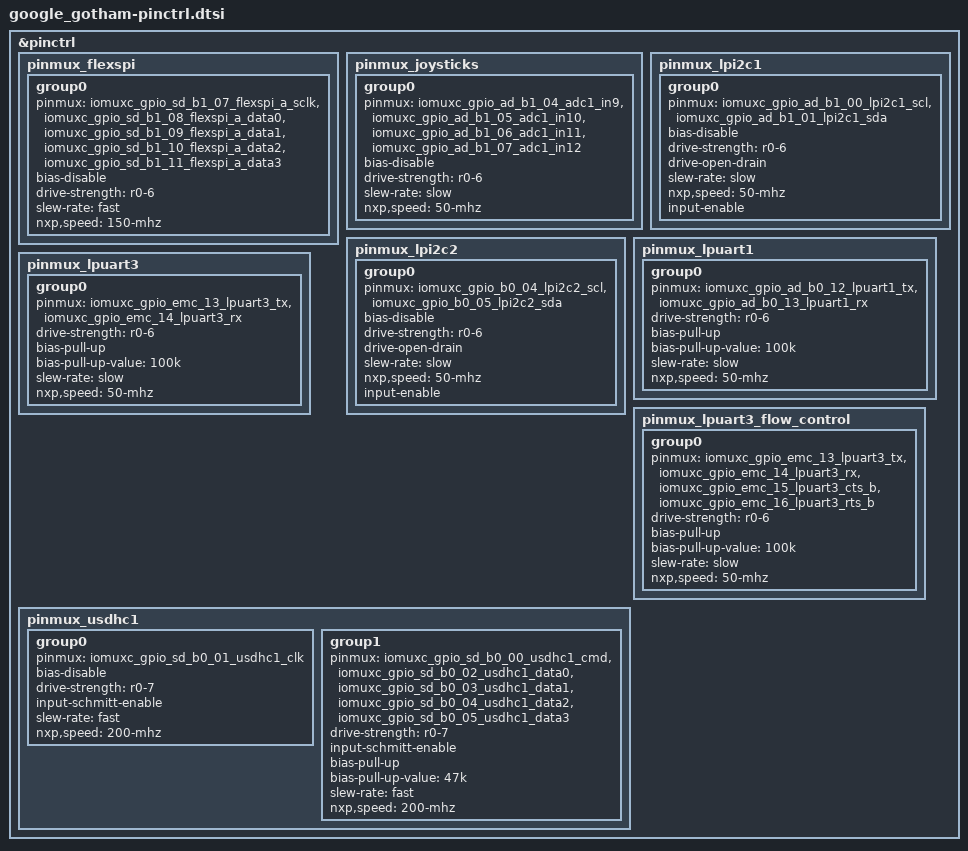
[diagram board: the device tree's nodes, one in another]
/*
 * Copyright 2025 NXP
 * All rights reserved.
 *
 * SPDX-License-Identifier: BSD-3-Clause
 */

/***********************************************************************************************************************
 * This file was generated by the MCUXpresso Config Tools. Any manual edits made to this file
 * will be overwritten if the respective MCUXpresso Config Tools is used to update this file.
 **********************************************************************************************************************/

#include <nxp/nxp_imx/rt/mimxrt1062dvl6a-pinctrl.dtsi>

&pinctrl {

	/* Configures pin routing and optionally pin electrical features. */
	pinmux_flexspi: pinmux_flexspi {
		group0 {
			pinmux = <&iomuxc_gpio_sd_b1_07_flexspi_a_sclk>,
				<&iomuxc_gpio_sd_b1_08_flexspi_a_data0>,
				<&iomuxc_gpio_sd_b1_09_flexspi_a_data1>,
				<&iomuxc_gpio_sd_b1_10_flexspi_a_data2>,
				<&iomuxc_gpio_sd_b1_11_flexspi_a_data3>;
			bias-disable;
			drive-strength = "r0-6";
			slew-rate = "fast";
			nxp,speed = "150-mhz";
		};
	};

	/* Configures pin routing and optionally pin electrical features. */
	pinmux_joysticks: pinmux_joysticks {
		group0 {
			pinmux = <&iomuxc_gpio_ad_b1_04_adc1_in9>,
				<&iomuxc_gpio_ad_b1_05_adc1_in10>,
				<&iomuxc_gpio_ad_b1_06_adc1_in11>,
				<&iomuxc_gpio_ad_b1_07_adc1_in12>;
			bias-disable;
			drive-strength = "r0-6";
			slew-rate = "slow";
			nxp,speed = "50-mhz";
		};
	};

	/* Configures pin routing and optionally pin electrical features. */
	pinmux_lpi2c1: pinmux_lpi2c1 {
		group0 {
			pinmux = <&iomuxc_gpio_ad_b1_00_lpi2c1_scl>,
				<&iomuxc_gpio_ad_b1_01_lpi2c1_sda>;
			bias-disable;
			drive-strength = "r0-6";
			drive-open-drain;
			slew-rate = "slow";
			nxp,speed = "50-mhz";
			input-enable;
		};
	};

	/* Configures pin routing and optionally pin electrical features. */
	pinmux_lpi2c2: pinmux_lpi2c2 {
		group0 {
			pinmux = <&iomuxc_gpio_b0_04_lpi2c2_scl>,
				<&iomuxc_gpio_b0_05_lpi2c2_sda>;
			bias-disable;
			drive-strength = "r0-6";
			drive-open-drain;
			slew-rate = "slow";
			nxp,speed = "50-mhz";
			input-enable;
		};
	};

	/* Configures pin routing and optionally pin electrical features. */
	pinmux_lpuart1: pinmux_lpuart1 {
		group0 {
			pinmux = <&iomuxc_gpio_ad_b0_12_lpuart1_tx>,
				<&iomuxc_gpio_ad_b0_13_lpuart1_rx>;
			drive-strength = "r0-6";
			bias-pull-up;
			bias-pull-up-value = "100k";
			slew-rate = "slow";
			nxp,speed = "50-mhz";
		};
	};

	/* Configures pin routing and optionally pin electrical features. */
	pinmux_lpuart3: pinmux_lpuart3 {
		group0 {
			pinmux = <&iomuxc_gpio_emc_13_lpuart3_tx>,
				<&iomuxc_gpio_emc_14_lpuart3_rx>;
			drive-strength = "r0-6";
			bias-pull-up;
			bias-pull-up-value = "100k";
			slew-rate = "slow";
			nxp,speed = "50-mhz";
		};
	};

	/* Configures pin routing and optionally pin electrical features. */
	pinmux_lpuart3_flow_control: pinmux_lpuart3_flow_control {
		group0 {
			pinmux = <&iomuxc_gpio_emc_13_lpuart3_tx>,
				<&iomuxc_gpio_emc_14_lpuart3_rx>,
				<&iomuxc_gpio_emc_15_lpuart3_cts_b>,
				<&iomuxc_gpio_emc_16_lpuart3_rts_b>;
			drive-strength = "r0-6";
			bias-pull-up;
			bias-pull-up-value = "100k";
			slew-rate = "slow";
			nxp,speed = "50-mhz";
		};
	};

	/* Configures pin routing and optionally pin electrical features. */
	pinmux_usdhc1: pinmux_usdhc1 {
		group0 {
			pinmux = <&iomuxc_gpio_sd_b0_01_usdhc1_clk>;
			bias-disable;
			drive-strength = "r0-7";
			input-schmitt-enable;
			slew-rate = "fast";
			nxp,speed = "200-mhz";
		};
		group1 {
			pinmux = <&iomuxc_gpio_sd_b0_00_usdhc1_cmd>,
				<&iomuxc_gpio_sd_b0_02_usdhc1_data0>,
				<&iomuxc_gpio_sd_b0_03_usdhc1_data1>,
				<&iomuxc_gpio_sd_b0_04_usdhc1_data2>,
				<&iomuxc_gpio_sd_b0_05_usdhc1_data3>;
			drive-strength = "r0-7";
			input-schmitt-enable;
			bias-pull-up;
			bias-pull-up-value = "47k";
			slew-rate = "fast";
			nxp,speed = "200-mhz";
		};
	};

};
